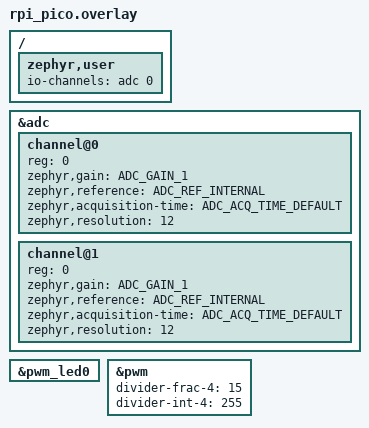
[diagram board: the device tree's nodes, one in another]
/*
 * SPDX-License-Identifier: Apache-2.0
 *
 * Copyright (c) 2022 TOKITA Hiroshi <tokita.hiroshi@fujitsu.com>
 */

#include <zephyr/dt-bindings/adc/adc.h>

/ {
	zephyr,user {
		io-channels = <&adc 0>;
	};
};

&adc {
	#address-cells = <1>;
	#size-cells = <0>;

	channel@0 {
		reg = <0>;
		zephyr,gain = "ADC_GAIN_1";
		zephyr,reference = "ADC_REF_INTERNAL";
		zephyr,acquisition-time = <ADC_ACQ_TIME_DEFAULT>;
		zephyr,resolution = <12>;
	};
	channel@1 {
		reg = <0>;
		zephyr,gain = "ADC_GAIN_1";
		zephyr,reference = "ADC_REF_INTERNAL";
		zephyr,acquisition-time = <ADC_ACQ_TIME_DEFAULT>;
		zephyr,resolution = <12>;
	};
};

&pwm_led0 {
	status = "okay";
};

&pwm {
	status = "okay";
	divider-frac-4 = <15>;
	divider-int-4 = <255>;
};
